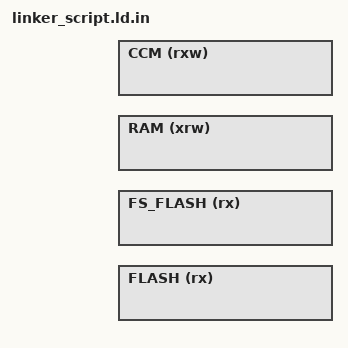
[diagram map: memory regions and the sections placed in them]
MEMORY
{
    FLASH (rx)   : ORIGIN = @flash_address@, LENGTH = @flash_size@
    FS_FLASH(rx) : ORIGIN = @flash_fs_address@, LENGTH = @flash_fs_size@
    RAM (xrw)    : ORIGIN = @ram_address@, LENGTH = @ram_size@
    CCM(rxw)     : ORIGIN = @ccm_address@, LENGTH = @ccm_size@

}

_heap_size = 0x2000;
_stack_size = 0x2000;

_fs_flash_start = ORIGIN(FS_FLASH);
_fs_flash_end = ORIGIN(FS_FLASH) + LENGTH(FS_FLASH);

_ram_start = ORIGIN(RAM);
_ram_end = ORIGIN(RAM) + LENGTH(RAM);

INCLUDE devices/arm/stm32/stm32_common.ld
